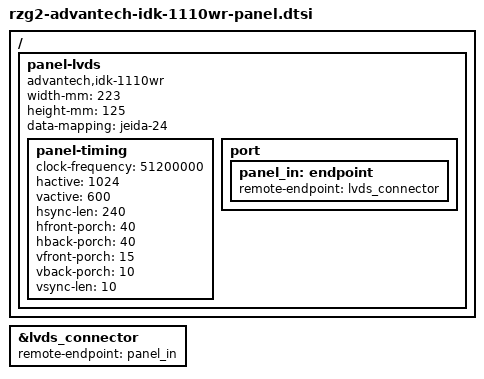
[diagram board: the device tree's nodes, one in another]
/ {
	panel-lvds {
		compatible = "advantech,idk-1110wr", "panel-lvds";
		width-mm = <223>;
		height-mm = <125>;
		data-mapping = "jeida-24";
		panel-timing {
			clock-frequency = <51200000>;
			hactive = <1024>;
			vactive = <600>;
			hsync-len = <240>;
			hfront-porch = <40>;
			hback-porch = <40>;
			vfront-porch = <15>;
			vback-porch = <10>;
			vsync-len = <10>;
		};
		port {
			panel_in: endpoint {
				remote-endpoint = <&lvds_connector>;
			};
		};
	};
};
&lvds_connector {
	remote-endpoint = <&panel_in>;
};
